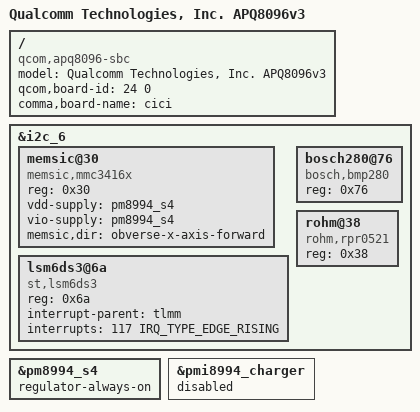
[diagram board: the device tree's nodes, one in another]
/* Copyright (c) 2015, The Linux Foundation. All rights reserved.
 *
 * This program is free software; you can redistribute it and/or modify
 * it under the terms of the GNU General Public License version 2 and
 * only version 2 as published by the Free Software Foundation.
 *
 * This program is distributed in the hope that it will be useful,
 * but WITHOUT ANY WARRANTY; without even the implied warranty of
 * MERCHANTABILITY or FITNESS FOR A PARTICULAR PURPOSE.  See the
 * GNU General Public License for more details.
 */


/dts-v1/;

#include "apq8096-v3.dtsi"
#include "msm-pmi8996.dtsi"
#include "apq8096-sbc.dtsi"
#include "dsi-panel-dijingILI9881C-720p-video.dtsi"

/ {
	model = "Qualcomm Technologies, Inc. APQ8096v3";
	compatible = "qcom,apq8096-sbc", "qcom,msm8996",
			"qcom,apq8096", "qcom,sbc";
	qcom,board-id = <24 0>;
	comma,board-name = "cici";
};

&i2c_6 {
	memsic@30 {
		compatible = "memsic,mmc3416x";
		reg = <0x30>;
		vdd-supply = <&pm8994_s4>;
		vio-supply = <&pm8994_s4>;
		memsic,dir = "obverse-x-axis-forward";
	};

	lsm6ds3@6a {
		compatible = "st,lsm6ds3";
		reg = <0x6a>;
		interrupt-parent = <&tlmm>;
		interrupts = <117 IRQ_TYPE_EDGE_RISING>;
	};

	bosch280@76 {
		compatible = "bosch,bmp280";
		reg = <0x76>;
	};

	rohm@38 {
		compatible = "rohm,rpr0521";
		reg = <0x38>;
	};
};

&pm8994_s4 {
	regulator-always-on;
};

&pmi8994_charger {
	status = "disabled";
};
